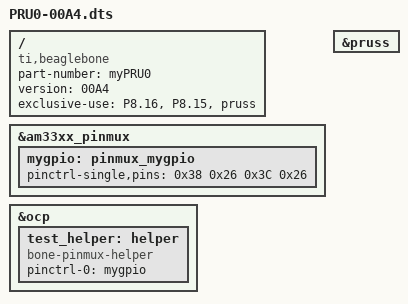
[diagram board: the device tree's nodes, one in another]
/dts-v1/;
/plugin/;

/ {
  compatible = "ti,beaglebone", "ti,beaglebone-black";


  part-number = "myPRU0";
  version = "00A4";

  exclusive-use =
    "P8.16",
    "P8.15",
    "pruss";

  fragment@0 {
    target = <&am33xx_pinmux>;
    __overlay__ {
      mygpio: pinmux_mygpio{
        pinctrl-single,pins = <
          0x38 0x26
          0x3C 0x26
         >;
      };
    };
  };

  fragment@1 {
    target = <&ocp>;
    __overlay__ {
      test_helper: helper {
        compatible = "bone-pinmux-helper";
        pinctrl-names = "default";
        pinctrl-0 = <&mygpio>;
        status = "okay";
      };
    };
  };

  fragment@2{
  target = <&pruss>;
   __overlay__ {
     status = "okay";
   };
  };
};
